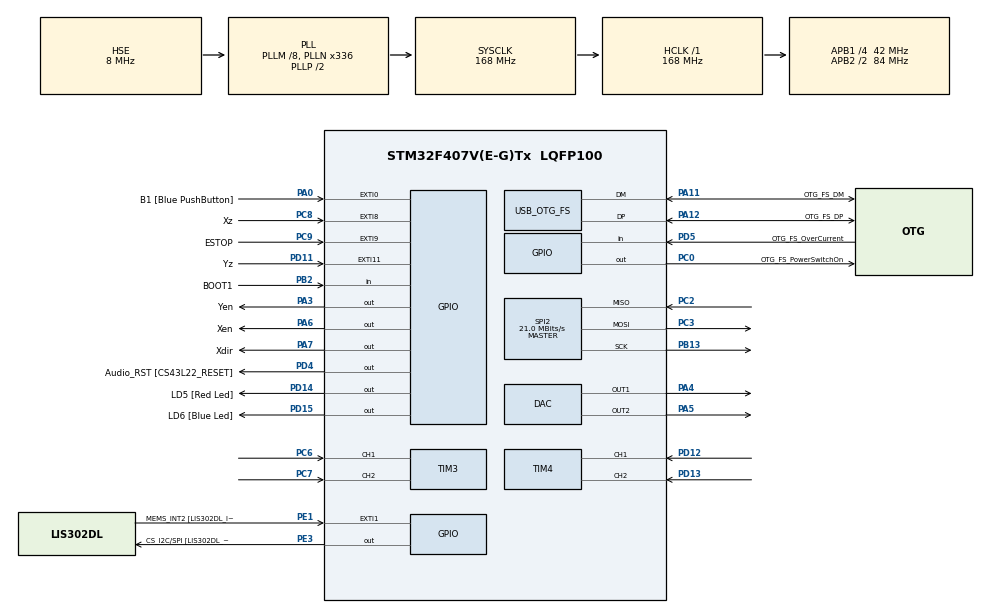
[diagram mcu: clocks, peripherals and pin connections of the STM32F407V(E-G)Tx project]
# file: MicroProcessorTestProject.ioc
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DAC.DAC_OutputBuffer=DAC_OUTPUTBUFFER_DISABLE
DAC.DAC_OutputBuffer2=DAC_OUTPUTBUFFER_DISABLE
Dma.Request0=TIM4_UP
Dma.TIM4_UP.0.Direction=DMA_PERIPH_TO_MEMORY
Dma.TIM4_UP.0.FIFOMode=DMA_FIFOMODE_DISABLE
Dma.TIM4_UP.0.Instance=DMA1_Stream6
Dma.TIM4_UP.0.MemDataAlignment=DMA_MDATAALIGN_HALFWORD
Dma.TIM4_UP.0.MemInc=DMA_MINC_ENABLE
Dma.TIM4_UP.0.Mode=DMA_NORMAL
Dma.TIM4_UP.0.PeriphDataAlignment=DMA_PDATAALIGN_HALFWORD
Dma.TIM4_UP.0.PeriphInc=DMA_PINC_DISABLE
Dma.TIM4_UP.0.Priority=DMA_PRIORITY_LOW
Mcu.Family=STM32F4
Mcu.Name=STM32F407V(E-G)Tx
Mcu.Package=LQFP100
NVIC.DMA1_Stream6_IRQn=true\:0\:0\:false\:false\:true\:false\:true\:true
NVIC.EXTI15_10_IRQn=true\:0\:0\:false\:false\:true\:true\:true\:true
NVIC.EXTI9_5_IRQn=true\:0\:0\:false\:false\:true\:true\:true\:true
NVIC.OTG_FS_IRQn=true\:0\:0\:false\:false\:true\:false\:true\:true
NVIC.PriorityGroup=NVIC_PRIORITYGROUP_0
NVIC.TIM1_BRK_TIM9_IRQn=true\:0\:0\:false\:false\:true\:true\:true\:true
NVIC.TIM3_IRQn=true\:0\:0\:false\:false\:true\:true\:true\:true
NVIC.TIM4_IRQn=true\:0\:0\:false\:false\:true\:true\:true\:true
NVIC.TIM6_DAC_IRQn=true\:0\:0\:false\:false\:true\:false\:true\:true
NVIC.TimeBase=TIM6_DAC_IRQn
NVIC.TimeBaseIP=TIM6
PA0-WKUP.GPIO_Label=B1 [Blue PushButton]
PA0-WKUP.GPIO_ModeDefaultEXTI=GPIO_MODE_EVT_RISING
PA0-WKUP.GPIO_PuPd=GPIO_NOPULL
PA0-WKUP.Signal=GPXTI0
PA10.GPIO_Label=OTG_FS_ID
PA10.GPIO_Mode=GPIO_MODE_AF_PP
PA10.GPIO_PuPd=GPIO_NOPULL
PA10.GPIO_Speed=GPIO_SPEED_FREQ_LOW
PA10.Signal=USB_OTG_FS_ID
PA11.GPIO_Label=OTG_FS_DM
PA11.GPIO_Mode=GPIO_MODE_AF_PP
PA11.GPIO_PuPd=GPIO_NOPULL
PA11.GPIO_Speed=GPIO_SPEED_FREQ_LOW
PA11.Mode=Device_Only
PA11.Signal=USB_OTG_FS_DM
PA12.GPIO_Label=OTG_FS_DP
PA12.GPIO_Mode=GPIO_MODE_AF_PP
PA12.GPIO_PuPd=GPIO_NOPULL
PA12.GPIO_Speed=GPIO_SPEED_FREQ_LOW
PA12.Mode=Device_Only
PA12.Signal=USB_OTG_FS_DP
PA13.GPIO_Label=SWDIO
PA13.Mode=Serial_Wire
PA13.Signal=SYS_JTMS-SWDIO
PA14.GPIO_Label=SWCLK
PA14.Mode=Serial_Wire
PA14.Signal=SYS_JTCK-SWCLK
PA3.GPIO_Label=Yen
PA3.GPIO_ModeDefaultOutputPP=GPIO_MODE_OUTPUT_PP
PA3.GPIO_PuPd=GPIO_NOPULL
PA3.GPIO_Speed=GPIO_SPEED_FREQ_HIGH
PA3.PinState=GPIO_PIN_SET
PA3.Signal=GPIO_Output
PA4.Signal=COMP_DAC1_group
PA5.Signal=COMP_DAC2_group
PA6.GPIO_Label=Xen
PA6.GPIO_PuPd=GPIO_NOPULL
PA6.GPIO_Speed=GPIO_SPEED_FREQ_HIGH
PA6.PinState=GPIO_PIN_SET
PA6.Signal=GPIO_Output
PA7.GPIO_Label=Xdir
PA7.GPIO_PuPd=GPIO_NOPULL
PA7.GPIO_Speed=GPIO_SPEED_FREQ_HIGH
PA7.PinState=GPIO_PIN_SET
PA7.Signal=GPIO_Output
PA9.GPIO_Label=VBUS_FS
PA9.GPIO_Mode=GPIO_MODE_INPUT
PA9.GPIO_PuPd=GPIO_NOPULL
PA9.Signal=USB_OTG_FS_VBUS
PB13.Mode=Full_Duplex_Master
PB13.Signal=SPI2_SCK
PB2.GPIO_Label=BOOT1
PB2.GPIO_Mode=GPIO_MODE_INPUT
PB2.GPIO_PuPd=GPIO_NOPULL
PB2.Signal=GPIO_Input
PC0.GPIO_Label=OTG_FS_PowerSwitchOn
PC0.GPIO_PuPd=GPIO_NOPULL
PC0.GPIO_Speed=GPIO_SPEED_FREQ_LOW
PC0.PinState=GPIO_PIN_SET
PC0.Signal=GPIO_Output
PC14-OSC32_IN.GPIO_Label=PC14-OSC32_IN
PC14-OSC32_IN.Mode=LSE-External-Oscillator
PC14-OSC32_IN.Signal=RCC_OSC32_IN
PC15-OSC32_OUT.GPIO_Label=PC15-OSC32_OUT
PC15-OSC32_OUT.Mode=LSE-External-Oscillator
PC15-OSC32_OUT.Signal=RCC_OSC32_OUT
PC2.Mode=Full_Duplex_Master
PC2.Signal=SPI2_MISO
PC3.Mode=Full_Duplex_Master
PC3.Signal=SPI2_MOSI
PC6.Signal=S_TIM3_CH1
PC7.Signal=S_TIM3_CH2
PC8.GPIO_Label=Xz
PC8.GPIO_ModeDefaultEXTI=GPIO_MODE_IT_RISING
PC8.Signal=GPXTI8
PC9.GPIO_Label=ESTOP
PC9.GPIO_ModeDefaultEXTI=GPIO_MODE_IT_FALLING
PC9.GPIO_PuPd=GPIO_PULLUP
PC9.Signal=GPXTI9
PD11.GPIO_Label=Yz
PD11.GPIO_ModeDefaultEXTI=GPIO_MODE_IT_RISING
PD11.Signal=GPXTI11
PD12.Signal=S_TIM4_CH1
PD13.Signal=S_TIM4_CH2
PD14.GPIO_Label=LD5 [Red Led]
PD14.GPIO_PuPd=GPIO_NOPULL
PD14.GPIO_Speed=GPIO_SPEED_FREQ_LOW
PD14.Signal=GPIO_Output
PD15.GPIO_Label=LD6 [Blue Led]
PD15.GPIO_PuPd=GPIO_NOPULL
PD15.GPIO_Speed=GPIO_SPEED_FREQ_LOW
PD15.Signal=GPIO_Output
PD4.GPIO_Label=Audio_RST [CS43L22_RESET]
PD4.GPIO_PuPd=GPIO_NOPULL
PD4.GPIO_Speed=GPIO_SPEED_FREQ_LOW
PD4.Signal=GPIO_Output
PD5.GPIO_Label=OTG_FS_OverCurrent
PD5.GPIO_Mode=GPIO_MODE_INPUT
PD5.GPIO_PuPd=GPIO_NOPULL
PD5.Signal=GPIO_Input
PE1.GPIO_Label=MEMS_INT2 [LIS302DL_INT2]
PE1.GPIO_ModeDefaultEXTI=GPIO_MODE_EVT_RISING
PE1.GPIO_PuPd=GPIO_NOPULL
PE1.Signal=GPXTI1
PE3.GPIO_Label=CS_I2C/SPI [LIS302DL_CS_I2C/SPI]
PE3.GPIO_PuPd=GPIO_NOPULL
PE3.GPIO_Speed=GPIO_SPEED_FREQ_LOW
PE3.Signal=GPIO_Output
PH0-OSC_IN.GPIO_Label=PH0-OSC_IN
PH0-OSC_IN.Mode=HSE-External-Oscillator
PH0-OSC_IN.Signal=RCC_OSC_IN
PH1-OSC_OUT.GPIO_Label=PH1-OSC_OUT
PH1-OSC_OUT.Mode=HSE-External-Oscillator
PH1-OSC_OUT.Signal=RCC_OSC_OUT
ProjectManager.HeapSize=0x600
ProjectManager.StackSize=0x400
ProjectManager.TargetToolchain=STM32CubeIDE
RCC.48MHZClocksFreq_Value=48000000
RCC.AHBFreq_Value=168000000
RCC.APB1CLKDivider=RCC_HCLK_DIV4
RCC.APB1Freq_Value=42000000
RCC.APB1TimFreq_Value=84000000
RCC.APB2CLKDivider=RCC_HCLK_DIV2
RCC.APB2Freq_Value=84000000
RCC.APB2TimFreq_Value=168000000
RCC.CortexFreq_Value=168000000
RCC.HCLKFreq_Value=168000000
RCC.HSE_VALUE=8000000
RCC.HSI_VALUE=16000000
RCC.PLLM=8
RCC.PLLN=336
RCC.PLLQ=7
RCC.SYSCLKFreq_VALUE=168000000
RCC.SYSCLKSource=RCC_SYSCLKSOURCE_PLLCLK
RCC.VCOOutputFreq_Value=336000000
SH.COMP_DAC1_group.0=DAC_OUT1,DAC_OUT1
SH.COMP_DAC2_group.0=DAC_OUT2,DAC_OUT2
SH.S_TIM3_CH1.0=TIM3_CH1,Encoder_Interface
SH.S_TIM3_CH2.0=TIM3_CH2,Encoder_Interface
SH.S_TIM4_CH1.0=TIM4_CH1,Encoder_Interface
SH.S_TIM4_CH2.0=TIM4_CH2,Encoder_Interface
SPI2.CalculateBaudRate=21.0 MBits/s
SPI2.Direction=SPI_DIRECTION_2LINES
SPI2.Mode=SPI_MODE_MASTER
SPI2.VirtualType=VM_MASTER
TIM3.EncoderMode=TIM_ENCODERMODE_TI12
TIM4.EncoderMode=TIM_ENCODERMODE_TI12
TIM9.Period=5000
TIM9.Prescaler=168-1
USB_DEVICE.CLASS_NAME_FS=CDC
USB_DEVICE.VirtualMode-CDC_FS=Cdc
USB_DEVICE.VirtualModeFS=Cdc_FS
USB_OTG_FS.VirtualMode=Device_Only
VP_SYS_VS_tim6.Mode=TIM6
VP_TIM9_VS_ClockSourceINT.Mode=Internal
VP_USB_DEVICE_VS_USB_DEVICE_CDC_FS.Mode=CDC_FS
board=STM32F407G-DISC1

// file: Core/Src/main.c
/* USER CODE BEGIN Header */
/**
  ******************************************************************************
  * @file           : main.c
  * @brief          : Main program body
  ******************************************************************************
  * @attention
  *
  * Copyright (c) 2023 STMicroelectronics.
  * All rights reserved.
  *
  * This software is licensed under terms that can be found in the LICENSE file
  * in the root directory of this software component.
  * If no LICENSE file comes with this software, it is provided AS-IS.
  *
  ******************************************************************************
  */
/* USER CODE END Header */
#include "main.h"
#include "dac.h"
#include "dma.h"
#include "spi.h"
#include "tim.h"
#include "usb_device.h"
#include "gpio.h"

/* USER CODE BEGIN Includes */
#include "myMain.h"
/* USER CODE END Includes */

/* USER CODE BEGIN PV */
uint32_t mainTimerCount = 0;
/* USER CODE END PV */

void SystemClock_Config(void);

int main(void)
{

  /* MCU Configuration--------------------------------------------------------*/

  /* Reset of all peripherals, Initializes the Flash interface and the Systick. */
  HAL_Init();

  /* Configure the system clock */
  SystemClock_Config();

  /* Initialize all configured peripherals */
  MX_GPIO_Init();
  MX_DMA_Init();
  MX_SPI2_Init();
  MX_DAC_Init();
  MX_TIM3_Init();
  MX_TIM4_Init();
  MX_TIM9_Init();
  MX_USB_DEVICE_Init();
  /* USER CODE BEGIN 2 */

  myInit(&hdac, &htim3, &htim4, &htim9);

  /* USER CODE END 2 */

  /* Infinite loop */
  while (1)
  {

    /* USER CODE BEGIN 3 */
	  myLoopInternals();
  }
  /* USER CODE END 3 */
}

void SystemClock_Config(void)
{
  RCC_OscInitTypeDef RCC_OscInitStruct = {0};
  RCC_ClkInitTypeDef RCC_ClkInitStruct = {0};

  /** Configure the main internal regulator output voltage
  */
  __HAL_RCC_PWR_CLK_ENABLE();
  __HAL_PWR_VOLTAGESCALING_CONFIG(PWR_REGULATOR_VOLTAGE_SCALE1);

  /** Initializes the RCC Oscillators according to the specified parameters
  * in the RCC_OscInitTypeDef structure.
  */
  RCC_OscInitStruct.OscillatorType = RCC_OSCILLATORTYPE_HSE;
  RCC_OscInitStruct.HSEState = RCC_HSE_ON;
  RCC_OscInitStruct.PLL.PLLState = RCC_PLL_ON;
  RCC_OscInitStruct.PLL.PLLSource = RCC_PLLSOURCE_HSE;
  RCC_OscInitStruct.PLL.PLLM = 8;
  RCC_OscInitStruct.PLL.PLLN = 336;
  RCC_OscInitStruct.PLL.PLLP = RCC_PLLP_DIV2;
  RCC_OscInitStruct.PLL.PLLQ = 7;
  if (HAL_RCC_OscConfig(&RCC_OscInitStruct) != HAL_OK)
  {
    Error_Handler();
  }

  /** Initializes the CPU, AHB and APB buses clocks
  */
  RCC_ClkInitStruct.ClockType = RCC_CLOCKTYPE_HCLK|RCC_CLOCKTYPE_SYSCLK
                              |RCC_CLOCKTYPE_PCLK1|RCC_CLOCKTYPE_PCLK2;
  RCC_ClkInitStruct.SYSCLKSource = RCC_SYSCLKSOURCE_PLLCLK;
  RCC_ClkInitStruct.AHBCLKDivider = RCC_SYSCLK_DIV1;
  RCC_ClkInitStruct.APB1CLKDivider = RCC_HCLK_DIV4;
  RCC_ClkInitStruct.APB2CLKDivider = RCC_HCLK_DIV2;

  if (HAL_RCC_ClockConfig(&RCC_ClkInitStruct, FLASH_LATENCY_5) != HAL_OK)
  {
    Error_Handler();
  }
}

void HAL_TIM_PeriodElapsedCallback(TIM_HandleTypeDef *htim)
{
  if (htim->Instance == TIM6) {
    HAL_IncTick();
  }
  /* USER CODE BEGIN Callback 1 */
  else
  {
	  my_HAL_TIM_PeriodElapsedCallback(htim);
  }
  /* USER CODE END Callback 1 */
}

void Error_Handler(void)
{
  __disable_irq();
  while (1)
  {
  }
}
